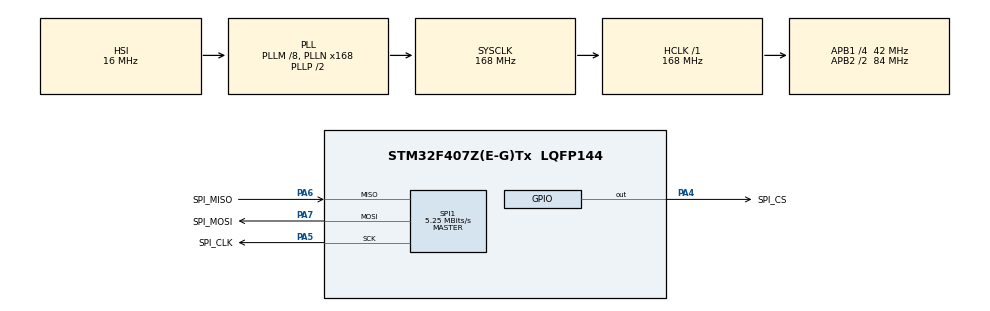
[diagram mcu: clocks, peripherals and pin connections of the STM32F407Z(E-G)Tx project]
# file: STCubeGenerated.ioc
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Mcu.Family=STM32F4
Mcu.Name=STM32F407Z(E-G)Tx
Mcu.Package=LQFP144
NVIC.PriorityGroup=NVIC_PRIORITYGROUP_4
NVIC.SPI1_IRQn=true\:0\:0\:false\:false\:true
PA4.GPIO_Label=SPI_CS
PA4.GPIO_Speed=GPIO_SPEED_FREQ_VERY_HIGH
PA4.PinState=GPIO_PIN_SET
PA4.Signal=GPIO_Output
PA5.GPIO_Label=SPI_CLK
PA5.Mode=Full_Duplex_Master
PA5.Signal=SPI1_SCK
PA6.GPIO_Label=SPI_MISO
PA6.Mode=Full_Duplex_Master
PA6.Signal=SPI1_MISO
PA7.GPIO_Label=SPI_MOSI
PA7.Mode=Full_Duplex_Master
PA7.Signal=SPI1_MOSI
PH0-OSC_IN.GPIO_Label=OSC1
PH0-OSC_IN.Mode=HSE-External-Clock-Source
PH0-OSC_IN.Signal=RCC_OSC_IN
PH1-OSC_OUT.GPIO_Label=OSC2
PH1-OSC_OUT.Mode=HSE-External-Clock-Source
PH1-OSC_OUT.Signal=RCC_OSC_OUT
ProjectManager.HeapSize=0x200
ProjectManager.StackSize=0x400
ProjectManager.TargetToolchain=MDK-ARM V5
RCC.48MHZClocksFreq_Value=84000000
RCC.AHBFreq_Value=168000000
RCC.APB1CLKDivider=RCC_HCLK_DIV4
RCC.APB1Freq_Value=42000000
RCC.APB1TimFreq_Value=84000000
RCC.APB2CLKDivider=RCC_HCLK_DIV2
RCC.APB2Freq_Value=84000000
RCC.APB2TimFreq_Value=168000000
RCC.CortexFreq_Value=168000000
RCC.HCLKFreq_Value=168000000
RCC.HSE_VALUE=8000000
RCC.HSI_VALUE=16000000
RCC.LSE_VALUE=32768
RCC.PLLM=8
RCC.PLLN=168
RCC.SYSCLKFreq_VALUE=168000000
RCC.SYSCLKSource=RCC_SYSCLKSOURCE_PLLCLK
RCC.VCOOutputFreq_Value=336000000
SPI1.BaudRatePrescaler=SPI_BAUDRATEPRESCALER_16
SPI1.CLKPolarity=SPI_POLARITY_LOW
SPI1.CalculateBaudRate=5.25 MBits/s
SPI1.Direction=SPI_DIRECTION_2LINES
SPI1.Mode=SPI_MODE_MASTER
SPI1.VirtualType=VM_MASTER
board=STCubeGenerated

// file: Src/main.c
/**
  ******************************************************************************
  * File Name          : main.c
  * Description        : Main program body
  ******************************************************************************
  ** This notice applies to any and all portions of this file
  * that are not between comment pairs USER CODE BEGIN and
  * USER CODE END. Other portions of this file, whether
  * inserted by the user or by software development tools
  * are owned by their respective copyright owners.
  *
  * COPYRIGHT(c) 2018 STMicroelectronics
  *
  * Redistribution and use in source and binary forms, with or without modification,
  * are permitted provided that the following conditions are met:
  *   1. Redistributions of source code must retain the above copyright notice,
  *      this list of conditions and the following disclaimer.
  *   2. Redistributions in binary form must reproduce the above copyright notice,
  *      this list of conditions and the following disclaimer in the documentation
  *      and/or other materials provided with the distribution.
  *   3. Neither the name of STMicroelectronics nor the names of its contributors
  *      may be used to endorse or promote products derived from this software
  *      without specific prior written permission.
  *
  * THIS SOFTWARE IS PROVIDED BY THE COPYRIGHT HOLDERS AND CONTRIBUTORS "AS IS"
  * AND ANY EXPRESS OR IMPLIED WARRANTIES, INCLUDING, BUT NOT LIMITED TO, THE
  * IMPLIED WARRANTIES OF MERCHANTABILITY AND FITNESS FOR A PARTICULAR PURPOSE ARE
  * DISCLAIMED. IN NO EVENT SHALL THE COPYRIGHT HOLDER OR CONTRIBUTORS BE LIABLE
  * FOR ANY DIRECT, INDIRECT, INCIDENTAL, SPECIAL, EXEMPLARY, OR CONSEQUENTIAL
  * DAMAGES (INCLUDING, BUT NOT LIMITED TO, PROCUREMENT OF SUBSTITUTE GOODS OR
  * SERVICES; LOSS OF USE, DATA, OR PROFITS; OR BUSINESS INTERRUPTION) HOWEVER
  * CAUSED AND ON ANY THEORY OF LIABILITY, WHETHER IN CONTRACT, STRICT LIABILITY,
  * OR TORT (INCLUDING NEGLIGENCE OR OTHERWISE) ARISING IN ANY WAY OUT OF THE USE
  * OF THIS SOFTWARE, EVEN IF ADVISED OF THE POSSIBILITY OF SUCH DAMAGE.
  *
  ******************************************************************************
  */
#include "main.h"
#include "stm32f4xx_hal.h"

/* USER CODE BEGIN Includes */
#include "bma2x2.h"
//#include "myiic.h"
/* USER CODE END Includes */

SPI_HandleTypeDef hspi1;

/* USER CODE BEGIN PV */
/* Private variables ---------------------------------------------------------*/

/* USER CODE END PV */

void SystemClock_Config(void);
static void MX_GPIO_Init(void);
static void MX_SPI1_Init(void);

/* USER CODE BEGIN PFP */
/* Private function prototypes -----------------------------------------------*/

/* USER CODE END PFP */

int main(void)
{
	unsigned int i = 0;
  /* USER CODE BEGIN 1 */
	struct bma2x2_accel_data sample_xyz;
	struct fifo_configuration fifo_conf;
	s16	accel_x_s16, accel_y_s16, accel_z_s16 = BMA2x2_INIT_VALUE;
  /* USER CODE END 1 */

  /* MCU Configuration----------------------------------------------------------*/

  /* Reset of all peripherals, Initializes the Flash interface and the Systick. */
  HAL_Init();

  /* USER CODE BEGIN Init */
	//fifo_conf.
  /* USER CODE END Init */

  /* Configure the system clock */
  SystemClock_Config();

  /* USER CODE BEGIN SysInit */
	//IIC_Init();
  /* USER CODE END SysInit */

  /* Initialize all configured peripherals */
  MX_GPIO_Init();
  MX_SPI1_Init();

  /* USER CODE BEGIN 2 */
	bma2x2_data_readout_template();
  /* USER CODE END 2 */

  /* Infinite loop */
  while (1)
  {

  /* USER CODE BEGIN 3 */

		//bma2x2_read_fifo_data(&fifo_conf);

	bma2x2_read_accel_x(&accel_x_s16);
	/* Read the accel Y data*/
	bma2x2_read_accel_y(&accel_y_s16);
	/* Read the accel Z data*/
	bma2x2_read_accel_z(&accel_z_s16);

	//	bma2x2_read_accel_xyz(&sample_xyz);
		HAL_Delay(1);
		i++;
  }
  /* USER CODE END 3 */

}

/** System Clock Configuration
*/
void SystemClock_Config(void)
{

  RCC_OscInitTypeDef RCC_OscInitStruct;
  RCC_ClkInitTypeDef RCC_ClkInitStruct;

    /**Configure the main internal regulator output voltage
    */
  __HAL_RCC_PWR_CLK_ENABLE();

  __HAL_PWR_VOLTAGESCALING_CONFIG(PWR_REGULATOR_VOLTAGE_SCALE1);

    /**Initializes the CPU, AHB and APB busses clocks
    */
  RCC_OscInitStruct.OscillatorType = RCC_OSCILLATORTYPE_HSI;
  RCC_OscInitStruct.HSIState = RCC_HSI_ON;
  RCC_OscInitStruct.HSICalibrationValue = 16;
  RCC_OscInitStruct.PLL.PLLState = RCC_PLL_ON;
  RCC_OscInitStruct.PLL.PLLSource = RCC_PLLSOURCE_HSI;
  RCC_OscInitStruct.PLL.PLLM = 8;
  RCC_OscInitStruct.PLL.PLLN = 168;
  RCC_OscInitStruct.PLL.PLLP = RCC_PLLP_DIV2;
  RCC_OscInitStruct.PLL.PLLQ = 4;
  if (HAL_RCC_OscConfig(&RCC_OscInitStruct) != HAL_OK)
  {
    _Error_Handler(__FILE__, __LINE__);
  }

    /**Initializes the CPU, AHB and APB busses clocks
    */
  RCC_ClkInitStruct.ClockType = RCC_CLOCKTYPE_HCLK|RCC_CLOCKTYPE_SYSCLK
                              |RCC_CLOCKTYPE_PCLK1|RCC_CLOCKTYPE_PCLK2;
  RCC_ClkInitStruct.SYSCLKSource = RCC_SYSCLKSOURCE_PLLCLK;
  RCC_ClkInitStruct.AHBCLKDivider = RCC_SYSCLK_DIV1;
  RCC_ClkInitStruct.APB1CLKDivider = RCC_HCLK_DIV4;
  RCC_ClkInitStruct.APB2CLKDivider = RCC_HCLK_DIV2;

  if (HAL_RCC_ClockConfig(&RCC_ClkInitStruct, FLASH_LATENCY_5) != HAL_OK)
  {
    _Error_Handler(__FILE__, __LINE__);
  }

    /**Configure the Systick interrupt time
    */
  HAL_SYSTICK_Config(HAL_RCC_GetHCLKFreq()/1000);

    /**Configure the Systick
    */
  HAL_SYSTICK_CLKSourceConfig(SYSTICK_CLKSOURCE_HCLK);

  /* SysTick_IRQn interrupt configuration */
  HAL_NVIC_SetPriority(SysTick_IRQn, 0, 0);
}

/* SPI1 init function */
static void MX_SPI1_Init(void)
{

  hspi1.Instance = SPI1;
  hspi1.Init.Mode = SPI_MODE_MASTER;
  hspi1.Init.Direction = SPI_DIRECTION_2LINES;
  hspi1.Init.DataSize = SPI_DATASIZE_8BIT;
  hspi1.Init.CLKPolarity = SPI_POLARITY_LOW;
  hspi1.Init.CLKPhase = SPI_PHASE_1EDGE;
  hspi1.Init.NSS = SPI_NSS_SOFT;
  hspi1.Init.BaudRatePrescaler = SPI_BAUDRATEPRESCALER_16;
  hspi1.Init.FirstBit = SPI_FIRSTBIT_MSB;
  hspi1.Init.TIMode = SPI_TIMODE_DISABLE;
  hspi1.Init.CRCCalculation = SPI_CRCCALCULATION_DISABLE;
  hspi1.Init.CRCPolynomial = 10;
  if (HAL_SPI_Init(&hspi1) != HAL_OK)
  {
    _Error_Handler(__FILE__, __LINE__);
  }

}

/** Configure pins as
        * Analog
        * Input
        * Output
        * EVENT_OUT
        * EXTI
*/
static void MX_GPIO_Init(void)
{

  GPIO_InitTypeDef GPIO_InitStruct;

  /* GPIO Ports Clock Enable */
  __HAL_RCC_GPIOH_CLK_ENABLE();
  __HAL_RCC_GPIOA_CLK_ENABLE();
	__HAL_RCC_GPIOB_CLK_ENABLE();
  /*Configure GPIO pin Output Level */
  HAL_GPIO_WritePin(GPIOB, GPIO_PIN_6, GPIO_PIN_SET);

  /*Configure GPIO pin : SPI_CS_Pin */
  GPIO_InitStruct.Pin = GPIO_PIN_6;
  GPIO_InitStruct.Mode = GPIO_MODE_OUTPUT_PP;
  GPIO_InitStruct.Pull = GPIO_NOPULL;
  GPIO_InitStruct.Speed = GPIO_SPEED_FREQ_VERY_HIGH;
  HAL_GPIO_Init(GPIOB, &GPIO_InitStruct);
	HAL_GPIO_WritePin(GPIOB, GPIO_PIN_6, GPIO_PIN_SET);
}

void _Error_Handler(char * file, int line)
{
  while(1)
  {
  }
}

/************************ (C) COPYRIGHT STMicroelectronics *****END OF FILE****/
